# STM32F107 register map
File version: 1.1
CPU: CM3 r1p1, little endian, no MPU, no FPU, 4 interrupt priority bits
Registers are 32-bit, read-write, reset 0x0 unless marked. A register's access mark holds for its fields unless they carry their own. Offsets are from the block's base; [hi:lo] are bit positions; lines under a group give offsets from that group; {n}, {i} and the like mark numbered series; 'fields as' and 'values as' point back to an identical list.

## OTG_FS_HOST — USB on the go full speed
Base 0x50000400
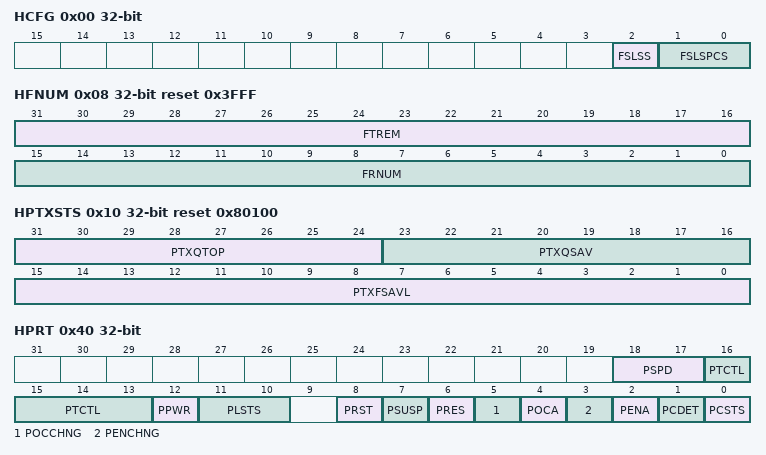
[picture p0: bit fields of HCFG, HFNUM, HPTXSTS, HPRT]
0x00 HCFG — OTG_FS host configuration register (OTG_FS_HCFG)
  [2] FSLSS — FS- and LS-only support
  [1:0] FSLSPCS — FS/LS PHY clock select
0x04 HFIR reset 0xEA60 — OTG_FS Host frame interval register
  [15:0] FRIVL — Frame interval
0x08 HFNUM ro reset 0x3FFF — OTG_FS host frame number/frame time remaining register (OTG_FS_HFNUM)
  [31:16] FTREM — Frame time remaining
  [15:0] FRNUM — Frame number
0x10 HPTXSTS access per field reset 0x80100 — OTG_FS_Host periodic transmit FIFO/queue status register (OTG_FS_HPTXSTS)
  [31:24] PTXQTOP ro — Top of the periodic transmit request queue
  [23:16] PTXQSAV ro — Periodic transmit request queue space available
  [15:0] PTXFSAVL rw — Periodic transmit data FIFO space available
0x14 HAINT ro — OTG_FS Host all channels interrupt register
  [15:0] HAINT — Channel interrupts
0x18 HAINTMSK — OTG_FS host all channels interrupt mask register
  [15:0] HAINTM — Channel interrupt mask
0x40 HPRT access per field — OTG_FS host port control and status register (OTG_FS_HPRT)
  [18:17] PSPD ro — Port speed
  [16:13] PTCTL rw — Port test control
  [12] PPWR rw — Port power
  [11:10] PLSTS ro — Port line status
  [8] PRST rw — Port reset
  [7] PSUSP rw — Port suspend
  [6] PRES rw — Port resume
  [5] POCCHNG rw — Port overcurrent change
  [4] POCA ro — Port overcurrent active
  [3] PENCHNG rw — Port enable/disable change
  [2] PENA rw — Port enable
  [1] PCDET rw — Port connect detected
  [0] PCSTS ro — Port connect status
{0x100+0x20*i} HC{i} (i=0..7) group — Host channel
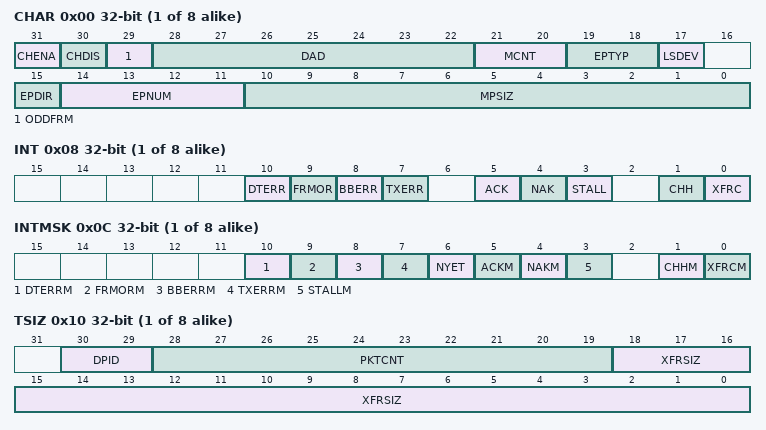
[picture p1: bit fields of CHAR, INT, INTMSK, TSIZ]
  0x00 CHAR — OTG_FS host channel-0 characteristics register (OTG_FS_HCCHAR0)
    [31] CHENA — Channel enable
    [30] CHDIS — Channel disable
    [29] ODDFRM — Odd frame
    [28:22] DAD — Device address
    [21:20] MCNT — Multicount
    [19:18] EPTYP — Endpoint type
    [17] LSDEV — Low-speed device
    [15] EPDIR — Endpoint direction
    [14:11] EPNUM — Endpoint number
    [10:0] MPSIZ — Maximum packet size
  0x08 INT — OTG_FS host channel-0 interrupt register (OTG_FS_HCINT0)
    [10] DTERR — Data toggle error
    [9] FRMOR — Frame overrun
    [8] BBERR — Babble error
    [7] TXERR — Transaction error
    [5] ACK — ACK response received/transmitted interrupt
    [4] NAK — NAK response received interrupt
    [3] STALL — STALL response received interrupt
    [1] CHH — Channel halted
    [0] XFRC — Transfer completed
  0x0C INTMSK — OTG_FS host channel-0 mask register (OTG_FS_HCINTMSK0)
    [10] DTERRM — Data toggle error mask
    [9] FRMORM — Frame overrun mask
    [8] BBERRM — Babble error mask
    [7] TXERRM — Transaction error mask
    [6] NYET — response received interrupt mask
    [5] ACKM — ACK response received/transmitted interrupt mask
    [4] NAKM — NAK response received interrupt mask
    [3] STALLM — STALL response received interrupt mask
    [1] CHHM — Channel halted mask
    [0] XFRCM — Transfer completed mask
  0x10 TSIZ — OTG_FS host channel-0 transfer size register
    [30:29] DPID — Data PID
    [28:19] PKTCNT — Packet count
    [18:0] XFRSIZ — Transfer size

## OTG_FS_PWRCLK — USB on the go full speed
Base 0x50000E00
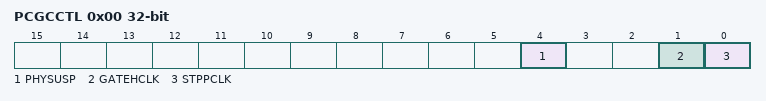
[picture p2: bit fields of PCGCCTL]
0x00 PCGCCTL — OTG_FS power and clock gating control register (OTG_FS_PCGCCTL)
  [4] PHYSUSP — PHY Suspended
  [1] GATEHCLK
  [0] STPPCLK — Stop PHY clock

## DAC — Digital to analog converter
Base 0x40007400
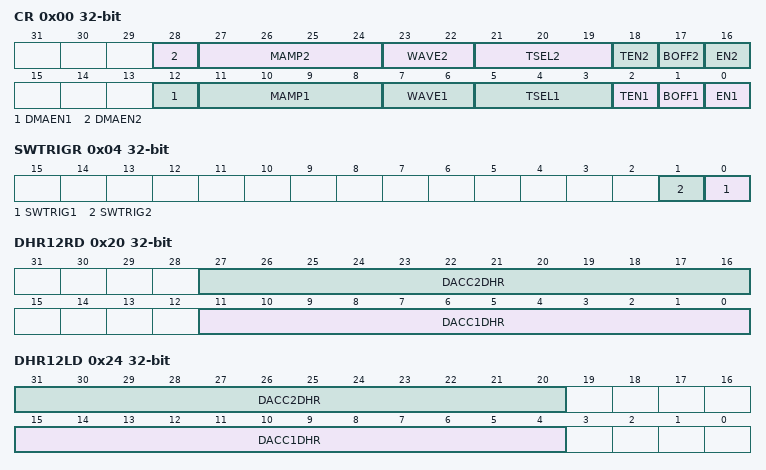
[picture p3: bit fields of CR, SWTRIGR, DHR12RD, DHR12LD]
0x00 CR — Control register (DAC_CR)
  [21:19] TSEL2 — DAC channel2 trigger selection
    0=Tim6Trgo (Timer 6 TRGO event); 1=Tim3Trgo (Timer 3 TRGO event); 2=Tim7Trgo (Timer 7 TRGO event); 3=Tim5Trgo (Timer 5 TRGO event); 4=Tim2Trgo (Timer 2 TRGO event); 5=Tim4Trgo (Timer 4 TRGO event); 6=Exti9 (EXTI line 9); 7=Software trigger
  [16n-4] DMAEN{n} (n=1..2) — DAC channel{n} DMA enable
    0=Disabled (DAC channel X DMA mode disabled); 1=Enabled (DAC channel X DMA mode enabled)
  [16n-5:16n-8] MAMP{n} (n=1..2) — DAC channel{n} mask/amplitude selector
    0=Amp1 (Unmask bit0 of LFSR/ triangle amplitude equal to 1); 1=Amp3 (Unmask bits[1:0] of LFSR/ triangle amplitude equal to 3); 2=Amp7 (Unmask bits[2:0] of LFSR/ triangle amplitude equal to 7); 3=Amp15 (Unmask bits[3:0] of LFSR/ triangle amplitude equal to 15); 4=Amp31 (Unmask bits[4:0] of LFSR/ triangle amplitude equal to 31); 5=Amp63 (Unmask bits[5:0] of LFSR/ triangle amplitude equal 63); 6=Amp127 (Unmask bits[6:0] of LFSR/ triangle amplitude equal to 127); 7=Amp255 (Unmask bits[7:0] of LFSR/ triangle amplitude equal to 255); 8=Amp511 (Unmask bits[8:0] of LFSR/ triangle amplitude equal to 511); 9=Amp1023 (Unmask bits[9:0] of LFSR/ triangle amplitude equal to 1023); 10=Amp2047 (Unmask bits[10:0] of LFSR/ triangle amplitude equal to 2047); other=Amp4095 (Unmask bits[11:0] of LFSR/ triangle amplitude equal to 4095)
  [16n-9:16n-10] WAVE{n} (n=1..2) — DAC channel{n} noise/triangle wave generation enable
    0=Disabled (Wave generation disabled); 1=Noise wave generation enabled; other=Triangle wave generation enabled
  [5:3] TSEL1 — DAC channel1 trigger selection
    values as TSEL2
  [16n-14] TEN{n} (n=1..2) — DAC channel{n} trigger enable
    0=Disabled (DAC channel X trigger disabled); 1=Enabled (DAC channel X trigger enabled)
  [16n-15] BOFF{n} (n=1..2) — DAC channel{n} output buffer disable
    0=Enabled (DAC channel X output buffer enabled); 1=Disabled (DAC channel X output buffer disabled)
  [16n-16] EN{n} (n=1..2) — DAC channel{n} enable
    0=Disabled (DAC channel X disabled); 1=Enabled (DAC channel X enabled)
0x04 SWTRIGR wo — DAC software trigger register (DAC_SWTRIGR)
  [n-1] SWTRIG{n} (n=1..2) — DAC channel{n} software trigger
    0=Disabled (DAC channel X software trigger disabled); 1=Enabled (DAC channel X software trigger enabled)
0x08 DHR12R{i} (i=1..2; step 0xC) — channel{i} 12-bit right-aligned data holding register
  [11:0] DACCDHR — DAC channel1 12-bit right-aligned data
{0x0+0xC*i} DHR12L{i} (i=1..2) — channel{i} 12-bit left aligned data holding register
  [15:4] DACCDHR — DAC channel1 12-bit left-aligned data
{0x4+0xC*i} DHR8R{i} (i=1..2) — channel{i} 8-bit right aligned data holding register
  [7:0] DACCDHR — DAC channel1 8-bit right-aligned data
0x20 DHR12RD — Dual DAC 12-bit right-aligned data holding register (DAC_DHR12RD), Bits 31:28 Reserved, Bits 15:12 Reserved
  [16n-5:16n-16] DACC{n}DHR (n=1..2) — DAC channel{n} 12-bit right-aligned data
0x24 DHR12LD — DUAL DAC 12-bit left aligned data holding register (DAC_DHR12LD), Bits 19:16 Reserved, Bits 3:0 Reserved
  [16n-1:16n-12] DACC{n}DHR (n=1..2) — DAC channel{n} 12-bit left-aligned data
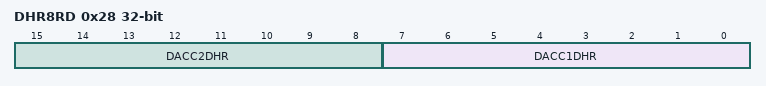
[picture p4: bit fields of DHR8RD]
0x28 DHR8RD — DUAL DAC 8-bit right aligned data holding register (DAC_DHR8RD), Bits 31:16 Reserved
  [8n-1:8n-8] DACC{n}DHR (n=1..2) — DAC channel{n} 8-bit right-aligned data
{0x28+4i} DOR{i} (i=1..2) ro — channel{i} data output register
  [11:0] DACCDOR — DAC channel1 data output
